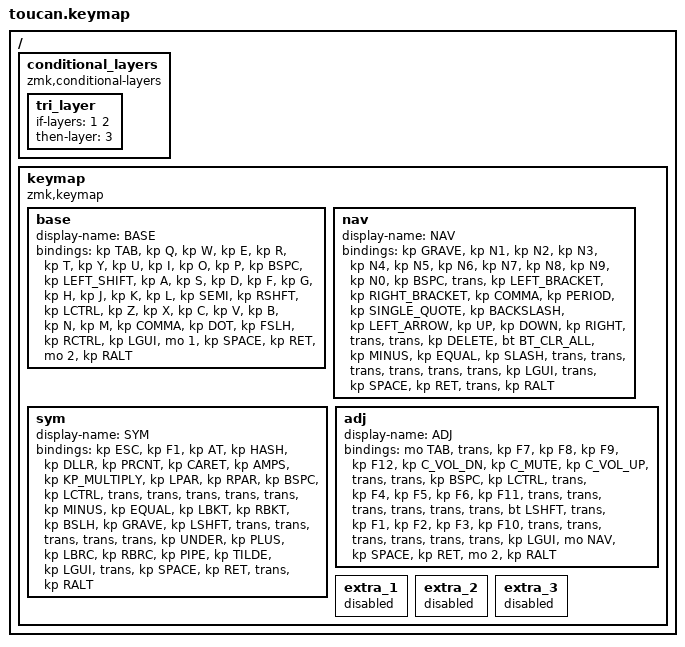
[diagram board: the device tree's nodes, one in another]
#include <behaviors.dtsi>
#include <dt-bindings/zmk/bt.h>
#include <dt-bindings/zmk/keys.h>

#define BASE 0
#define NAV  1
#define SYM  2
#define ADJ  3

/ {
    conditional_layers {
        compatible = "zmk,conditional-layers";

        tri_layer {
            if-layers = <1 2>;
            then-layer = <3>;
        };
    };

    keymap {
        compatible = "zmk,keymap";

        base {
            display-name = "BASE";
            bindings = <
&kp TAB  &kp Q  &kp W  &kp E  &kp R  &kp T  &kp Y  &kp U  &kp I  &kp O  &kp P  &kp BSPC  &kp LEFT_SHIFT  &kp A  &kp S  &kp D  &kp F  &kp G  &kp H  &kp J  &kp K  &kp L  &kp SEMI  &kp RSHFT  &kp LCTRL  &kp Z  &kp X  &kp C  &kp V  &kp B  &kp N  &kp M  &kp COMMA  &kp DOT  &kp FSLH  &kp RCTRL  &kp LGUI  &mo 1  &kp SPACE  &kp RET  &mo 2  &kp RALT
            >;
        };

        nav {
            display-name = "NAV";
            bindings = <
&kp GRAVE  &kp N1  &kp N2  &kp N3  &kp N4  &kp N5  &kp N6  &kp N7  &kp N8  &kp N9  &kp N0  &kp BSPC  &trans  &kp LEFT_BRACKET  &kp RIGHT_BRACKET  &kp COMMA  &kp PERIOD  &kp SINGLE_QUOTE  &kp BACKSLASH  &kp LEFT_ARROW  &kp UP  &kp DOWN  &kp RIGHT  &trans  &trans  &kp DELETE  &bt BT_CLR_ALL  &kp MINUS  &kp EQUAL  &kp SLASH  &trans  &trans  &trans  &trans  &trans  &trans  &kp LGUI  &trans  &kp SPACE  &kp RET  &trans  &kp RALT
            >;
        };

        sym {
            display-name = "SYM";
            bindings = <
&kp ESC  &kp F1  &kp AT  &kp HASH  &kp DLLR  &kp PRCNT  &kp CARET  &kp AMPS  &kp KP_MULTIPLY  &kp LPAR  &kp RPAR  &kp BSPC  &kp LCTRL  &trans  &trans  &trans  &trans  &trans  &kp MINUS  &kp EQUAL  &kp LBKT  &kp RBKT  &kp BSLH  &kp GRAVE  &kp LSHFT  &trans  &trans  &trans  &trans  &trans  &kp UNDER  &kp PLUS  &kp LBRC  &kp RBRC  &kp PIPE  &kp TILDE  &kp LGUI  &trans  &kp SPACE  &kp RET  &trans  &kp RALT
            >;
        };

        adj {
            display-name = "ADJ";
            bindings = <
&mo TAB  &trans  &kp F7  &kp F8  &kp F9  &kp F12  &kp C_VOL_DN  &kp C_MUTE  &kp C_VOL_UP  &trans  &trans  &kp BSPC  &kp LCTRL  &trans  &kp F4  &kp F5  &kp F6  &kp F11  &trans  &trans  &trans  &trans  &trans  &trans  &bt LSHFT  &trans  &kp F1  &kp F2  &kp F3  &kp F10  &trans  &trans  &trans  &trans  &trans  &trans  &kp LGUI  &mo NAV  &kp SPACE  &kp RET  &mo 2  &kp RALT
            >;
        };

        extra_1 { status = "reserved"; };

        extra_2 { status = "reserved"; };

        extra_3 { status = "reserved"; };
    };
};
